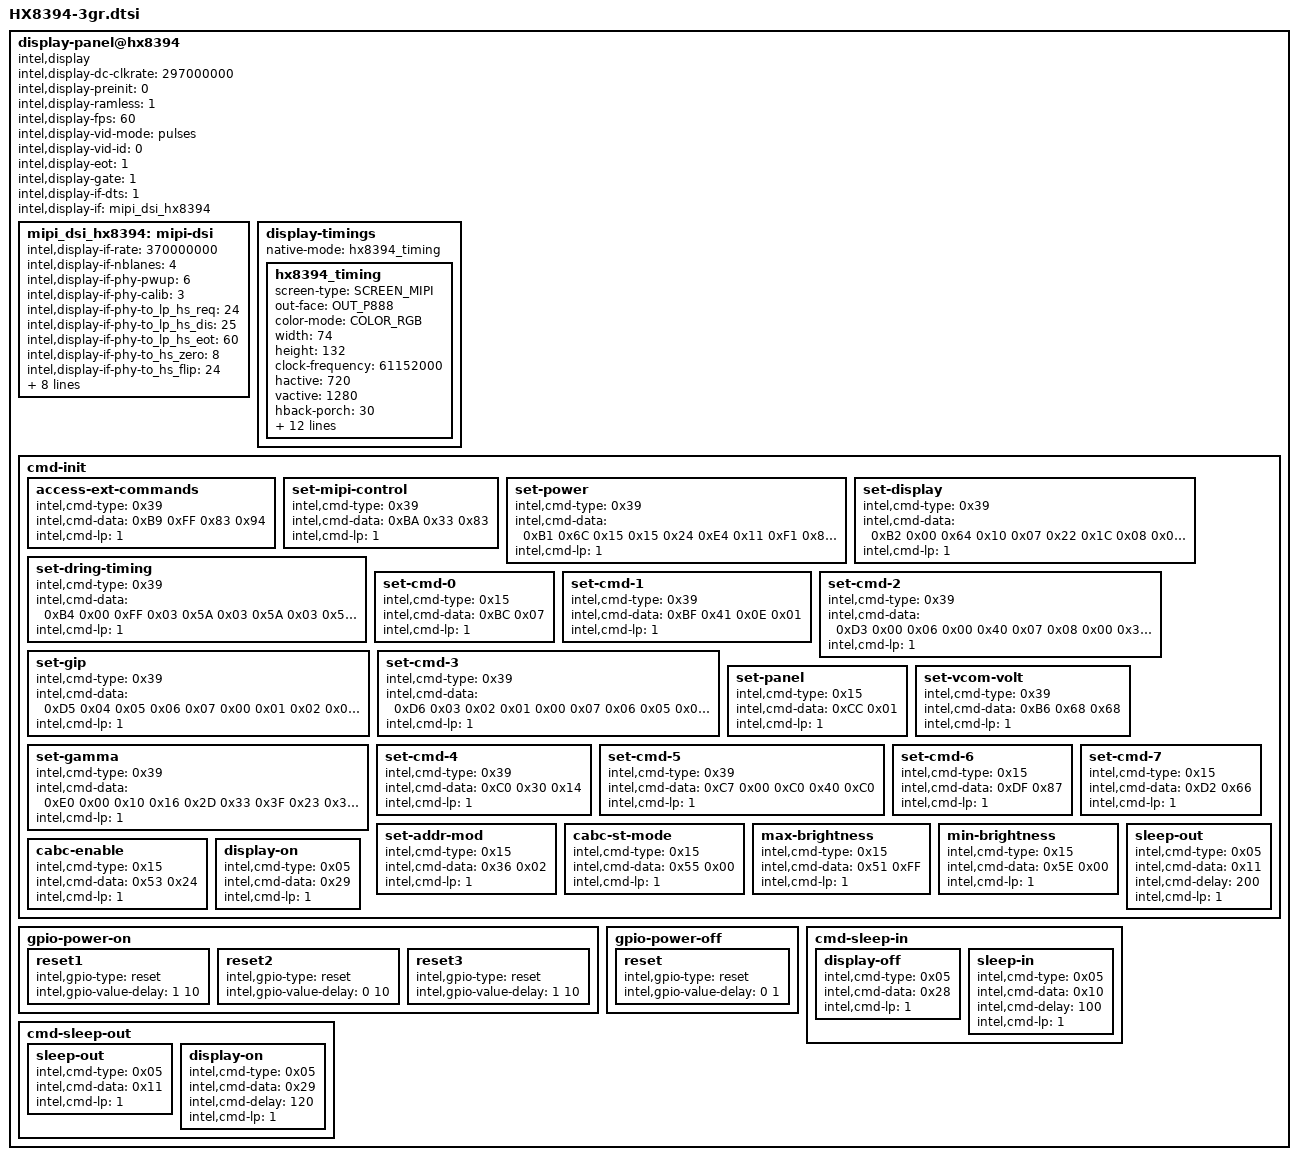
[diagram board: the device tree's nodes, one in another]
/*
 * definition at "include/dt-bindings/sofiafb/sofia_fb.h"
 */

display-panel@hx8394 {
	compatible = "intel,display";
	intel,display-dc-clkrate = <297000000>;
	intel,display-preinit = <0>;
	intel,display-ramless = <1>;
	intel,display-fps = <60>;
	intel,display-vid-mode = "pulses";
	intel,display-vid-id = <0>;
	intel,display-eot = <1>;
	intel,display-gate = <1>;
	intel,display-if-dts = <1>;
	intel,display-if = <&mipi_dsi_hx8394>;
	mipi_dsi_hx8394:mipi-dsi {
		intel,display-if-rate = <370000000>;
		intel,display-if-nblanes = <4>;
		intel,display-if-phy-pwup = <6>;
		intel,display-if-phy-calib = <3>;
		intel,display-if-phy-to_lp_hs_req = <24>;
		intel,display-if-phy-to_lp_hs_dis = <25>;
		intel,display-if-phy-to_lp_hs_eot = <60>;
		intel,display-if-phy-to_hs_zero = <8>;
		intel,display-if-phy-to_hs_flip = <24>;
		intel,display-if-phy-lp_clk_div = <31>;
		intel,display-if-phy-to_hs_clk_pre = <36>;
		intel,display-if-phy-to_hs_clk_post = <42>;
		intel,display-if-phy-data_delay = <7>;
		intel,display-if-phy-clock_delay = <7>;
		intel,display-if-phy-lp_tx_tfall = <2>;
		intel,display-if-phy-lp_tx_rise = <2>;
		intel,display-if-phy-lp_tx_vref = <31>;
	};

	display-timings {
		native-mode = <&hx8394_timing>;
		hx8394_timing: hx8394_timing {
			screen-type = <SCREEN_MIPI>;
			out-face    = <OUT_P888>;
			color-mode = <COLOR_RGB>;
			width = <74>;
			height = <132>;
			clock-frequency = <61152000>;
			hactive = <720>;
			vactive = <1280>;
			hback-porch = <30>;
			hfront-porch = <30>;
			vback-porch = <8>;
			vfront-porch = <8>;
			hsync-len = <4>;
			vsync-len = <4>;
			hsync-active = <0>;
			vsync-active = <0>;
			de-active = <0>;
			pixelclk-active = <0>;
			swap-rb = <0>;
			swap-rg = <0>;
			swap-gb = <0>;
		};
	};

	cmd-init {
		access-ext-commands {
			intel,cmd-type = <0x39>;
			intel,cmd-data = <0xB9 0xFF 0x83 0x94>;
			intel,cmd-lp = <1>;
		};
		set-mipi-control {
			intel,cmd-type = <0x39>;
			intel,cmd-data = <0xBA 0x33 0x83>;
			intel,cmd-lp = <1>;
		};
		set-power {
			intel,cmd-type = <0x39>;
			intel,cmd-data = <0xB1
				0x6C 0x15 0x15 0x24 0xE4 0x11 0xF1 0x80 0xE4 0x97
				0x23 0x80 0xC0 0xD2 0x58>;
			intel,cmd-lp = <1>;
		};
		set-display {
			intel,cmd-type = <0x39>;
			intel,cmd-data = <0xB2
				0x00 0x64 0x10 0x07 0x22 0x1C 0x08 0x08 0x1C 0x4D 0x00>;
			intel,cmd-lp = <1>;
		};
		set-dring-timing {
			intel,cmd-type = <0x39>;
			intel,cmd-data = <0xB4
				0x00 0xFF 0x03 0x5A 0x03 0x5A 0x03 0x5A 0x01 0x6A 0x30 0x6A>;
			intel,cmd-lp = <1>;
		};
		set-cmd-0 {
			intel,cmd-type = <0x15>;
			intel,cmd-data = <0xBC 0x07>;
			intel,cmd-lp = <1>;
		};
		set-cmd-1 {
			intel,cmd-type = <0x39>;
			intel,cmd-data = <0xBF 0x41 0x0E 0x01>;
			intel,cmd-lp = <1>;
		};
		set-cmd-2 {
			intel,cmd-type = <0x39>;
			intel,cmd-data = <0xD3
				0x00 0x06 0x00 0x40 0x07 0x08 0x00 0x32 0x10 0x07
				0x00 0x07 0x54 0x15 0x0F 0x05 0x04 0x02 0x12 0x10
				0x05 0x07 0x33 0x33 0x0B 0x0B 0x37 0x10 0x07 0x07>;
			intel,cmd-lp = <1>;
		};
		set-gip {
			intel,cmd-type = <0x39>;
			intel,cmd-data = <0xD5
				0x04 0x05 0x06 0x07 0x00 0x01 0x02 0x03 0x20 0x21
				0x22 0x23 0x18 0x18 0x18 0x18 0x18 0x18 0x18 0x18
				0x19 0x19 0x18 0x18 0x18 0x18 0x1B 0x1B 0x1A 0x1A
				0x18 0x18 0x18 0x18 0x18 0x18 0x18 0x18 0x18 0x18
				0x18 0x18 0x18 0x18>;
			intel,cmd-lp = <1>;
		};
		set-cmd-3 {
			intel,cmd-type = <0x39>;
			intel,cmd-data = <0xD6
				0x03 0x02 0x01 0x00 0x07 0x06 0x05 0x04 0x23 0x22
				0x21 0x20 0x18 0x18 0x18 0x18 0x18 0x18 0x58 0x58
				0x18 0x18 0x19 0x19 0x18 0x18 0x1B 0x1B 0x1A 0x1A
				0x18 0x18 0x18 0x18 0x18 0x18 0x18 0x18 0x18 0x18
				0x18 0x18 0x18 0x18>;
			intel,cmd-lp = <1>;
		};
		set-panel {
			intel,cmd-type = <0x15>;
			intel,cmd-data = <0xCC 0x01>;
			intel,cmd-lp = <1>;
		};
		set-vcom-volt {
			intel,cmd-type = <0x39>;
			intel,cmd-data = <0xB6 0x68 0x68>;
			intel,cmd-lp = <1>;
		};
		set-gamma {
			intel,cmd-type = <0x39>;
			intel,cmd-data = <0xE0
				0x00 0x10 0x16 0x2D 0x33 0x3F 0x23 0x3E 0x07 0x0B
				0x0D 0x17 0x0E 0x12 0x14 0x12 0x13 0x06 0x11 0x13
				0x18 0x00 0x0F 0x16 0x2E 0x33 0x3F 0x23 0x3D 0x07
				0x0B 0x0D 0x18 0x0F 0x12 0x14 0x12 0x14 0x07 0x11
				0x12 0x17>;
			intel,cmd-lp = <1>;
		};
		set-cmd-4 {
			intel,cmd-type = <0x39>;
			intel,cmd-data = <0xC0 0x30 0x14>;
			intel,cmd-lp = <1>;
		};
		set-cmd-5 {
			intel,cmd-type = <0x39>;
			intel,cmd-data = <0xC7 0x00 0xC0 0x40 0xC0>;
			intel,cmd-lp = <1>;
		};
		set-cmd-6 {
			intel,cmd-type = <0x15>;
			intel,cmd-data = <0xDF 0x87>;
			intel,cmd-lp = <1>;
		};
		set-cmd-7 {
			intel,cmd-type = <0x15>;
			intel,cmd-data = <0xD2 0x66>;
			intel,cmd-lp = <1>;
		};
		set-addr-mod {
			intel,cmd-type = <0x15>;
			intel,cmd-data = <0x36 0x02>;
			intel,cmd-lp = <1>;
		};
		cabc-st-mode{
			intel,cmd-type = <0x15>;
			intel,cmd-data = <0x55 0x00>;
			intel,cmd-lp = <1>;
		};
		max-brightness{
			intel,cmd-type = <0x15>;
			intel,cmd-data = <0x51 0xFF>;
			intel,cmd-lp = <1>;
		};
		min-brightness{
			intel,cmd-type = <0x15>;
			intel,cmd-data = <0x5E 0x00>;
			intel,cmd-lp = <1>;
		};
		cabc-enable{
			intel,cmd-type = <0x15>;
			intel,cmd-data = <0x53 0x24>;
			intel,cmd-lp = <1>;
		};
		sleep-out {
			intel,cmd-type = <0x05>;
			intel,cmd-data = <0x11>;
			intel,cmd-delay = <200>;
			intel,cmd-lp = <1>;
		};
		display-on {
			intel,cmd-type = <0x05>;
			intel,cmd-data = <0x29>;
			intel,cmd-lp = <1>;
		};
	};

	gpio-power-on {
		/*power_en {
			intel,gpio-type = "vhigh";
			intel,gpio-value-delay = <1 41>;
		};*/
		reset1 {
			intel,gpio-type = "reset";
			intel,gpio-value-delay = <1 10>;
		};
		reset2 {
			intel,gpio-type = "reset";
			intel,gpio-value-delay = <0 10>;
		};
		reset3 {
			intel,gpio-type = "reset";
			intel,gpio-value-delay = <1 10>;
		};
	};

	gpio-power-off {
		reset {
			intel,gpio-type = "reset";
			intel,gpio-value-delay = <0 1>;
		};
		/*power_en {
			intel,gpio-type = "vhigh";
			intel,gpio-value-delay = <0 0>;
		};*/
	};

	cmd-sleep-in {
		display-off {
			intel,cmd-type = <0x05>;
			intel,cmd-data = <0x28>;
			intel,cmd-lp = <1>;
		};
		sleep-in {
			intel,cmd-type = <0x05>;
			intel,cmd-data = <0x10>;
			intel,cmd-delay = <100>;
			intel,cmd-lp = <1>;
		};
	};

	cmd-sleep-out {
		sleep-out {
			intel,cmd-type = <0x05>;
			intel,cmd-data = <0x11>;
			intel,cmd-lp = <1>;
		};
		display-on {
			intel,cmd-type = <0x05>;
			intel,cmd-data = <0x29>;
			intel,cmd-delay = <120>;
			intel,cmd-lp = <1>;
		};
	};
};
